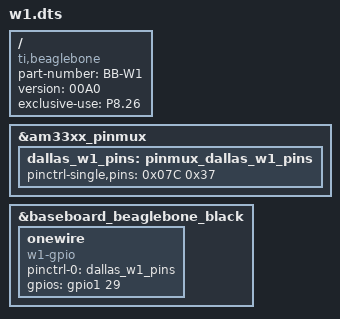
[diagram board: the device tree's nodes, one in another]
/dts-v1/;
/plugin/;

/{
    compatible = "ti,beaglebone", "ti,beaglebone-black";

	/* identification*/
    part-number = "BB-W1";
    version = "00A0";

    /* state the resources this cape uses */
    exclusive-use =
    "P8.26";   /* the pin header uses */
/*    "gpio0_2";*/ /* the hardware IP uses */

    fragment@0 {
        target = <&am33xx_pinmux>;
        __overlay__ {
            dallas_w1_pins: pinmux_dallas_w1_pins {
                pinctrl-single,pins = <0x07C 0x37>; /* GPIO1_2929292929292929292929292929292929292929292929292929292929 */
		    };
        };
    };

    fragment@1 {
        target = <&baseboard_beaglebone_black>;
        __overlay__ {
            onewire {
                compatible = "w1-gpio";
                pinctrl-names = "default";
                pinctrl-0 = <&dallas_w1_pins>;
                status = "okay";
                gpios = <&gpio1 29 0>;
            };
        };
    };
};
